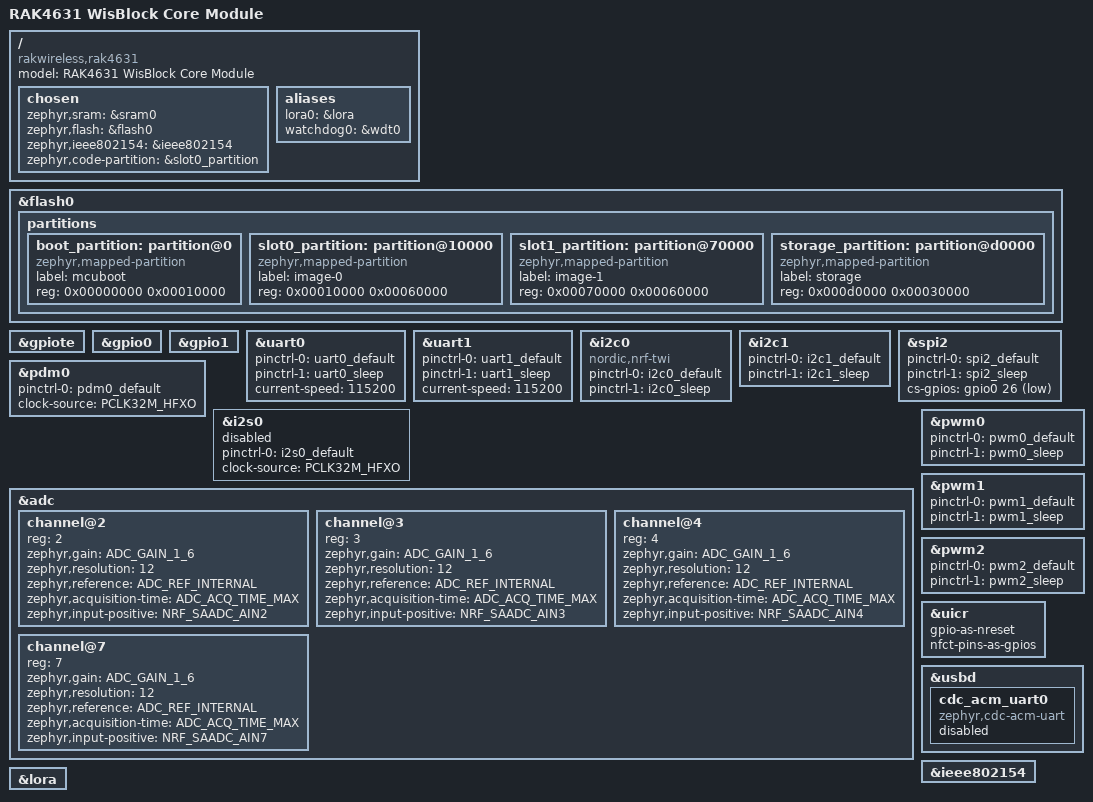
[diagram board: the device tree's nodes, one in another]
/*
 * Copyright (c) 2021 Guillaume Paquet <guillaume.paquet@smile.fr>
 * Copyright (c) 2026 JaeHwan Jin <jaehwan.jin@rakwireless.com>
 *
 * SPDX-License-Identifier: Apache-2.0
 */

/dts-v1/;
#include <rakwireless/rak4630.dtsi>
#include "rak4631-pinctrl.dtsi"

/ {
	model = "RAK4631 WisBlock Core Module";
	compatible = "rakwireless,rak4631";

	chosen {
		zephyr,sram = &sram0;
		zephyr,flash = &flash0;
		zephyr,ieee802154 = &ieee802154;
		zephyr,code-partition = &slot0_partition;
	};

	aliases {
		lora0 = &lora;
		watchdog0 = &wdt0;
	};
};

&flash0 {
	status = "okay";

	partitions {
		ranges;
		#address-cells = <1>;
		#size-cells = <1>;

		boot_partition: partition@0 {
			compatible = "zephyr,mapped-partition";
			label = "mcuboot";
			reg = <0x00000000 0x00010000>;
		};

		slot0_partition: partition@10000 {
			compatible = "zephyr,mapped-partition";
			label = "image-0";
			reg = <0x00010000 0x00060000>;
		};

		slot1_partition: partition@70000 {
			compatible = "zephyr,mapped-partition";
			label = "image-1";
			reg = <0x00070000 0x00060000>;
		};

		storage_partition: partition@d0000 {
			compatible = "zephyr,mapped-partition";
			label = "storage";
			reg = <0x000d0000 0x00030000>;
		};
	};
};

&gpiote {
	status = "okay";
};

&gpio0 {
	status = "okay";
};

&gpio1 {
	status = "okay";
};

&uart0 {
	pinctrl-0 = <&uart0_default>;
	pinctrl-1 = <&uart0_sleep>;
	pinctrl-names = "default", "sleep";
	current-speed = <115200>;
};

&uart1 {
	pinctrl-0 = <&uart1_default>;
	pinctrl-1 = <&uart1_sleep>;
	pinctrl-names = "default", "sleep";
	current-speed = <115200>;
};

&i2c0 {
	compatible = "nordic,nrf-twi";
	pinctrl-0 = <&i2c0_default>;
	pinctrl-1 = <&i2c0_sleep>;
	pinctrl-names = "default", "sleep";
};

&i2c1 {
	pinctrl-0 = <&i2c1_default>;
	pinctrl-1 = <&i2c1_sleep>;
	pinctrl-names = "default", "sleep";
};

&spi2 {
	pinctrl-0 = <&spi2_default>;
	pinctrl-1 = <&spi2_sleep>;
	pinctrl-names = "default", "sleep";

	cs-gpios = <&gpio0 26 GPIO_ACTIVE_LOW>;
};

&pdm0 {
	pinctrl-0 = <&pdm0_default>;
	pinctrl-names = "default";
	clock-source = "PCLK32M_HFXO";
};

&i2s0 {
	status = "disabled";
	pinctrl-0 = <&i2s0_default>;
	pinctrl-names = "default";
	clock-source = "PCLK32M_HFXO";
};

&adc {
	status = "okay";
	#address-cells = <1>;
	#size-cells = <0>;

	channel@2 {
		reg = <2>;
		zephyr,gain = "ADC_GAIN_1_6";
		zephyr,resolution = <12>;
		zephyr,reference = "ADC_REF_INTERNAL";
		zephyr,acquisition-time = <ADC_ACQ_TIME_MAX>;
		zephyr,input-positive = <NRF_SAADC_AIN2>;
	};

	channel@3 {
		reg = <3>;
		zephyr,gain = "ADC_GAIN_1_6";
		zephyr,resolution = <12>;
		zephyr,reference = "ADC_REF_INTERNAL";
		zephyr,acquisition-time = <ADC_ACQ_TIME_MAX>;
		zephyr,input-positive = <NRF_SAADC_AIN3>;
	};

	channel@4 {
		reg = <4>;
		zephyr,gain = "ADC_GAIN_1_6";
		zephyr,resolution = <12>;
		zephyr,reference = "ADC_REF_INTERNAL";
		zephyr,acquisition-time = <ADC_ACQ_TIME_MAX>;
		zephyr,input-positive = <NRF_SAADC_AIN4>;
	};

	channel@7 {
		reg = <7>;
		zephyr,gain = "ADC_GAIN_1_6";
		zephyr,resolution = <12>;
		zephyr,reference = "ADC_REF_INTERNAL";
		zephyr,acquisition-time = <ADC_ACQ_TIME_MAX>;
		zephyr,input-positive = <NRF_SAADC_AIN7>;
	};
};

&pwm0 {
	status = "okay";
	pinctrl-0 = <&pwm0_default>;
	pinctrl-1 = <&pwm0_sleep>;
	pinctrl-names = "default", "sleep";
};

&pwm1 {
	status = "okay";
	pinctrl-0 = <&pwm1_default>;
	pinctrl-1 = <&pwm1_sleep>;
	pinctrl-names = "default", "sleep";
};

&pwm2 {
	status = "okay";
	pinctrl-0 = <&pwm2_default>;
	pinctrl-1 = <&pwm2_sleep>;
	pinctrl-names = "default", "sleep";
};

&uicr {
	gpio-as-nreset;
	nfct-pins-as-gpios;
};

zephyr_udc0: &usbd {
	status = "okay";

	cdc_acm_uart0: cdc_acm_uart0 {
		status = "disabled";
		compatible = "zephyr,cdc-acm-uart";
	};
};

&ieee802154 {
	status = "okay";
};

&lora {
	status = "okay";
};

#include "wisblock.dtsi"
